# M3351 register map
File version: 1.0
Registers are 32-bit, read-write, reset 0x0 unless marked. A register's access mark holds for its fields unless they carry their own. Offsets are from the block's base; [hi:lo] are bit positions; lines under a group give offsets from that group; {n}, {i} and the like mark numbered series; 'fields as' and 'values as' point back to an identical list.

## PWM0 — PWM Register Map
Base 0x4005C000
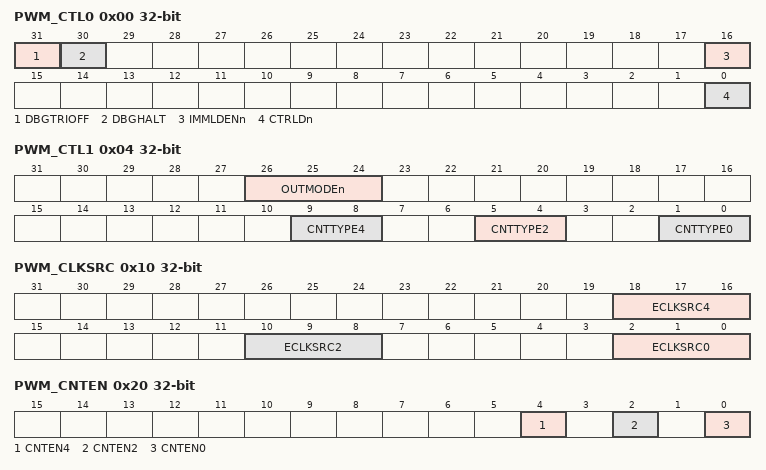
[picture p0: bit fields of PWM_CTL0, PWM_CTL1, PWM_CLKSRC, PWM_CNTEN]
0x00 PWM_CTL0 — PWM Control Register 0
  [31] DBGTRIOFF — ICE Debug Mode Acknowledge Disable Bit (Write Protect). PWM pin will keep output no matter ICE debug mode acknowledged or not. Note: This bit is write protected. Refer to SYS_REGLCTL register.
    0=ICE debug mode acknowledgement effects PWM output; 1=ICE debug mode acknowledgement disabled
  [30] DBGHALT — ICE Debug Mode Counter Halt (Write Protect). If counter halt is enabled, PWM all counters will keep current value until exit ICE debug mode. Note: This bit is write protected. Refer to SYS_REGLCTL register.
    0=ICE debug mode counter halt Disable; 1=ICE debug mode counter halt Enable
  [16] IMMLDENn — Immediately Load Enable Bits. Note: If IMMLDENn is enabled, WINLDENn and CTRLDn will be invalid.
    0=PERIOD will load to PBUF at the end point of each period. CMPDAT will load to CMPBUF at the end point or center point of each period by setting CTRLD bit; 1=PERIOD/CMPDAT will load to PBUF and CMPBUF immediately when software update PERIOD/CMPDAT
  [0] CTRLDn — Center Load Enable Bits. In up-down counter type, PERIOD will load to PBUF at the end point of each period. CMPDAT will load to CMPBUF at the center point of a period.
0x04 PWM_CTL1 — PWM Control Register 1
  [26:24] OUTMODEn — PWM Output Mode. Each bit n controls the output mode of corresponding PWM channel n. Note: When operating in group function, these bits must all set to the same mode.
    0=PWM independent mode; 1=PWM complementary mode
  [9:8] CNTTYPE4 — PWM Counter Behavior Type 4. The two bits control channel5 and channel4
    0=Up counter type (supported in capture mode); 1=Down count type (supported in capture mode); 2=Up-down counter type
  [5:4] CNTTYPE2 — PWM Counter Behavior Type 2. The two bits control channel3 and channel2
    values as CNTTYPE4
  [1:0] CNTTYPE0 — PWM Counter Behavior Type 0. The two bits control channel1 and channel0
    values as CNTTYPE4
0x10 PWM_CLKSRC — PWM Clock Source Register
  [all] fields
    0=PWMx_CLK, x denotes 0 or 1; {v}=TIMER{v-1} overflow (v=1..4)
  [18:16] ECLKSRC4 — PWM_CH45 External Clock Source Select
  [10:8] ECLKSRC2 — PWM_CH23 External Clock Source Select
  [2:0] ECLKSRC0 — PWM_CH01 External Clock Source Select
0x14 PWM_CLKPSC0_1 — PWM Clock Prescale Register 0/1
  [11:0] CLKPSC — PWM Counter Clock Prescale. The clock of PWM counter is decided by clock prescaler. Each PWM pair share one PWM counter clock prescaler. The clock of PWM counter is divided by (CLKPSC+ 1).
0x18 PWM_CLKPSC2_3 — PWM Clock Prescale Register 2/3
  fields as PWM_CLKPSC0_1
0x1C PWM_CLKPSC4_5 — PWM Clock Prescale Register 4/5
  fields as PWM_CLKPSC0_1
0x20 PWM_CNTEN — PWM Counter Enable Register
  [all] fields
    0=PWM Counter and clock prescaler Stop Running; 1=PWM Counter and clock prescaler Start Running
  [4] CNTEN4 — PWM Counter Enable Bit 4
  [2] CNTEN2 — PWM Counter Enable Bit 2
  [0] CNTEN0 — PWM Counter Enable Bit 0
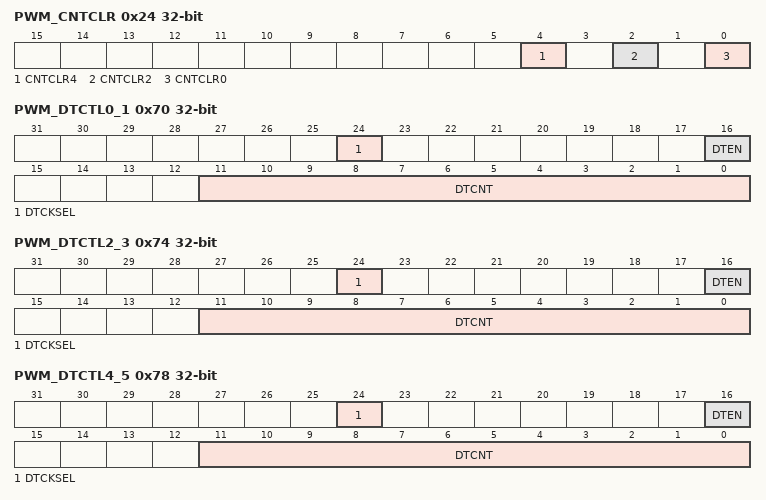
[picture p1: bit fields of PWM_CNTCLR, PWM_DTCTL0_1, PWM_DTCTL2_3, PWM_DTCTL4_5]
0x24 PWM_CNTCLR — PWM Clear Counter Register
  [all] fields
    0=No effect; 1=Clear 16-bit PWM counter to 0000H
  [4] CNTCLR4 — Clear PWM Counter Control Bit 4. It is automatically cleared by hardware.
  [2] CNTCLR2 — Clear PWM Counter Control Bit 2. It is automatically cleared by hardware.
  [0] CNTCLR0 — Clear PWM Counter Control Bit 0. It is automatically cleared by hardware.
0x30 PWM_PERIOD0 — PWM Period Register 0
  [15:0] PERIOD — PWM Period Register. Up-Count mode: In this mode, PWM counter counts from 0 to PERIOD, and restarts from 0. Down-Count mode: In this mode, PWM counter counts from PERIOD to 0, and restarts from PERIOD.
0x38 PWM_PERIOD2 — PWM Period Register 2
  fields as PWM_PERIOD0
0x40 PWM_PERIOD4 — PWM Period Register 4
  fields as PWM_PERIOD0
{0x50+4i} PWM_CMPDAT{i} (i=0..5) — PWM Comparator Register {i}
  [15:0] CMP — PWM Comparator Register. CMP is used to compar e with CNT to generate PWM waveform, interrupt and trigger EADC/ /DAC. In independent mode, PWM_CMPDAT0~5 denote as 6 independent PWM_CH0~5 compared point. In complementary mode, PWM_CMPDAT0, 2, 4 denote as first compared point, and PWM_CMPDAT1, 3, 5 denote as second compared point for the corresponding 3 complementary pairs PWM_CH0 and PWM_CH1, PWM_CH2 and PWM_CH3, PWM_CH4 and PWM_CH5.
0x70 PWM_DTCTL0_1 — PWM Dead-time Control Register 0/1
  [24] DTCKSEL — Dead-time Clock Select (Write Protect). Note: This bit is write protected. Refer to SYS_REGLCTL register.
    0=Dead-time clock source from PWM_CLK; 1=Dead-time clock source from prescaler output
  [16] DTEN — Enable Dead-time Insertion for PWM Pair (Write Protect). Dead-time insertion is only active when this pair of complementary PWM is enabled. If dead- time insertion is inactive, the outputs of pin pair are complementary without any delay. Note: This bit is write protected. Refer to SYS_REGLCTL register. Note: PWM pair means PWM_CH0, PWM_CH1 are a pair, PWM_CH2, PWM_CH3 are a pair and PWM_CH4, PWM_CH5 are a pair.
    0=Dead-time insertion Disabled on the pin pair; 1=Dead-time insertion Enabled on the pin pair
  [11:0] DTCNT — Dead-time Counter (Write Protect). The dead-time can be calculated from the following formula: Note: This bit is write protected. Refer to SYS_REGLCTL register.
0x74 PWM_DTCTL2_3 — PWM Dead-time Control Register 2/3
  fields as PWM_DTCTL0_1
0x78 PWM_DTCTL4_5 — PWM Dead-time Control Register 4/5
  fields as PWM_DTCTL0_1
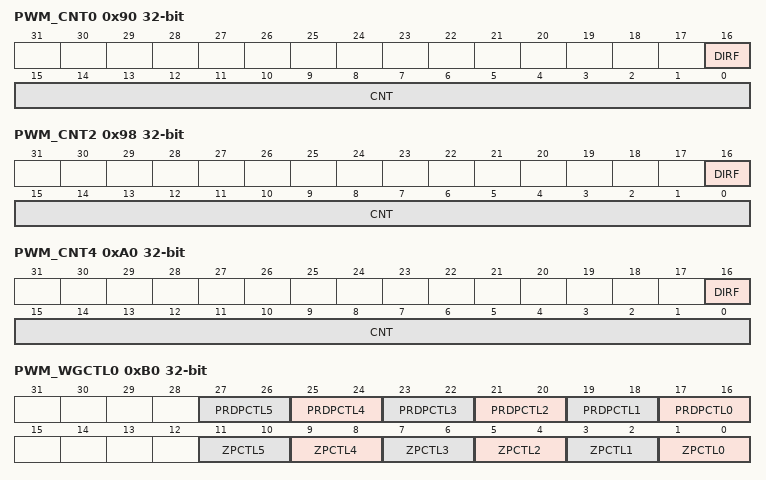
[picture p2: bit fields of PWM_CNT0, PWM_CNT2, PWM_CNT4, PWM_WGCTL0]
0x90 PWM_CNT0 ro — PWM Counter Register 0
  [16] DIRF — PWM Direction Indicator Flag (Read Only)
    0=Counter is counting down; 1=Counter is counting up
  [15:0] CNT — PWM Data Register (Read Only). User can monitor CNT to know the current value in 16-bit period counter.
0x98 PWM_CNT2 ro — PWM Counter Register 2
  fields as PWM_CNT0
0xA0 PWM_CNT4 ro — PWM Counter Register 4
  fields as PWM_CNT0
0xB0 PWM_WGCTL0 — PWM Generation Register 0
  [2n+17:2n+16] PRDPCTL{n} (n=0..5) — PWM Period/Center Point Control. Note 1: PWM can control output level when PWM counter counts to (PERIODn+1). Note 2: This bit is center point control when PWM counter operating in up-down counter type.
    0=Do nothing; 1=PWM period/center point output Low; 2=PWM period/center point output High; 3=PWM period/center point output Toggle
  [2n+1:2n] ZPCTL{n} (n=0..5) — PWM Zero Point Control. Note: PWM can control output level when PWM counter counts to 0.
    0=Do nothing; 1=PWM zero point output Low; 2=PWM zero point output High; 3=PWM zero point output Toggle
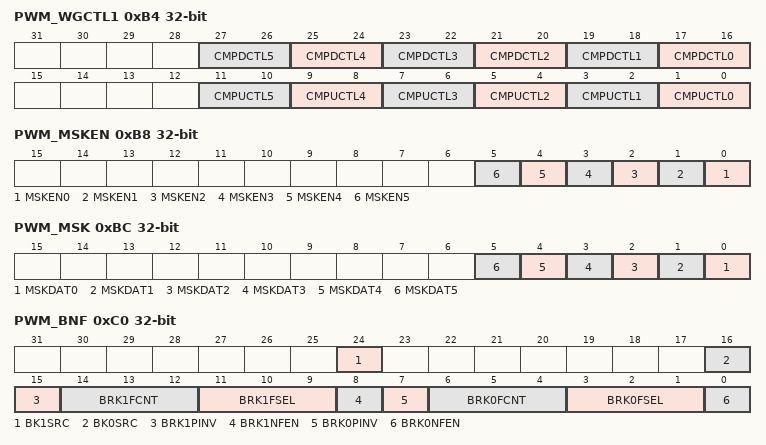
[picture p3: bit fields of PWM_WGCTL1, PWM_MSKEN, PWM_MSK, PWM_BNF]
0xB4 PWM_WGCTL1 — PWM Generation Register 1
  [2n+17:2n+16] CMPDCTL{n} (n=0..5) — PWM Compare Down Point Control. Note 1: PWM can control output level when PWM counter counts down to CMPDAT. Note 2: In complementary mode, CMPDCTL1, 3, 5 is used as another CMPDCTL for channel 0, 2, 4.
    0=Do nothing; 1=PWM compare down point output Low; 2=PWM compare down point output High; 3=PWM compare down point output Toggle
  [2n+1:2n] CMPUCTL{n} (n=0..5) — PWM Compare Up Point Control. Note 1: PWM can control output level when PWM counter counts up to CMPDAT. Note 2: In complementary mode, CMPUCTL1, 3, 5 is used as another CMPUCTL for channel 0, 2, 4.
    0=Do nothing; 1=PWM compare up point output Low; 2=PWM compare up point output High; 3=PWM compare up point output Toggle
0xB8 PWM_MSKEN — PWM Mask Enable Register
  [all] fields
    0=PWM output signal is non-masked; 1=PWM output signal is masked and output MSKDATn data
  [n] MSKEN{n} (n=0..5) — PWM Mask Enable Bits. The PWM output signal will be masked when this bit is enabled. The corresponding PWM channel n will output MSKDATn (PWM_MSK[5:0]) data.
0xBC PWM_MSK — PWM Mask Data Register
  [all] fields
    0=Output logic low to PWM channel n; 1=Output logic high to PWM channel n
  [n] MSKDAT{n} (n=0..5) — PWM Mask Data Bit. This data bit control the state of PWMn output pin, if corresponding mask function is enabled. Each bit n controls the corresponding PWM channel n.
0xC0 PWM_BNF — PWM Brake Noise Filter Register
  [24] BK1SRC — Brake 1 Pin Source Select. For PWM0 setting:
    0=Brake 1 pin source come from PWM0_BRAKE1. Brake 1 pin source come from PWM1_BRAKE1; 1=Brake 1 pin source come from PWM1_BRAKE1. Brake 1 pin source come from PWM0_BRAKE1
  [16] BK0SRC — Brake 0 Pin Source Select. For PWM0 setting:
    0=Brake 0 pin source come from PWM0_BRAKE0. Brake 0 pin source come from PWM1_BRAKE0; 1=Brake 0 pin source come from PWM1_BRAKE0. Brake 0 pin source come from PWM0_BRAKE0
  [15] BRK1PINV — Brake 1 Pin Inverse
    0=Brake pin event will be detected if PWMx_BRAKE1 pin status transfer from low to high in edge-detect, or pin status is high in level-detect; 1=Brake pin event will be detected if PWMx_BRAKE1 pin status transfer from high to low in edge-detect, or pin status is low in level-detect
  [14:12] BRK1FCNT — Brake 1 Edge Detector Filter Count. The register bits control the Brake1 filter counter to count from 0 to BRK1FCNT.
  [11:9] BRK1FSEL — Brake 1 Edge Detector Filter Clock Selection
    0=Filter clock = HCLK; 1=Filter clock = HCLK/2; 2=Filter clock = HCLK/4; 3=Filter clock = HCLK/8; 4=Filter clock = HCLK/16; 5=Filter clock = HCLK/32; 6=Filter clock = HCLK/64; 7=Filter clock = HCLK/128
  [8] BRK1NFEN — PWM Brake 1 Noise Filter Enable Bit
    0=Noise filter of PWM Brake 1 Disabled; 1=Noise filter of PWM Brake 1 Enabled
  [7] BRK0PINV — Brake 0 Pin Inverse
    0=brake pin event will be detected if PWMx_BRAKE0 pin status transfer from low to high in edge-detect, or pin status is high in level-detect; 1=brake pin event will be detected if PWMx_BRAKE0 pin status transfer from high to low in edge-detect, or pin status is low in level-detect
  [6:4] BRK0FCNT — Brake 0 Edge Detector Filter Count. The register bits control the Brake0 filter counter to count from 0 to BRK1FCNT.
  [3:1] BRK0FSEL — Brake 0 Edge Detector Filter Clock Selection
    values as BRK1FSEL
  [0] BRK0NFEN — PWM Brake 0 Noise Filter Enable Bit
    0=Noise filter of PWM Brake 0 Disabled; 1=Noise filter of PWM Brake 0 Enabled
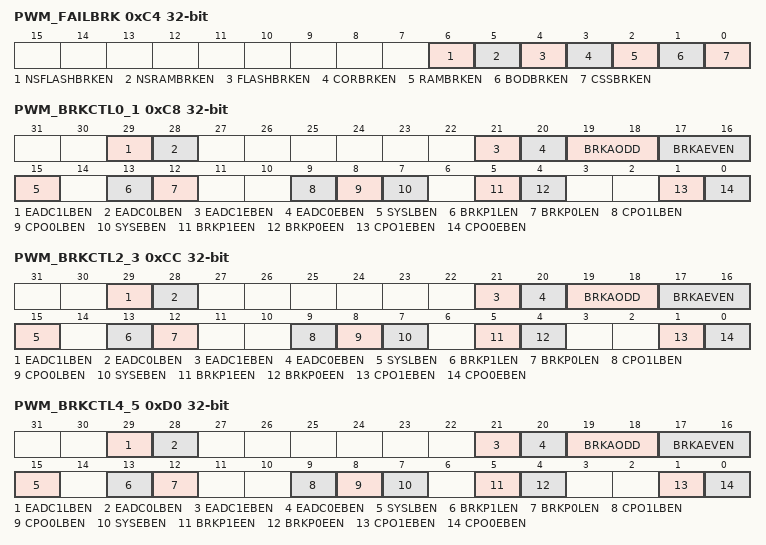
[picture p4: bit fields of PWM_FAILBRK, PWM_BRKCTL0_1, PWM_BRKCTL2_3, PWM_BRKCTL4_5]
0xC4 PWM_FAILBRK — PWM System Fail Brake Control Register
  [6] NSFLASHBRKEN — FLASH non security ECC Error Detection Trigger PWM Brake Function Enable Bit
    0=Brake Function triggered by FLASH non security ECCerror detection Disabled; 1=Brake Function triggered by FLASH non security ECCerror detection Enabled
  [5] NSRAMBRKEN — SRAM non security ECC Error Detection Trigger PWM Brake Function Enable Bit
    0=Brake Function triggered by SRAM non security ECCerror detection Disabled; 1=Brake Function triggered by SRAM non security ECCerror detection Enabled
  [4] FLASHBRKEN — FLASH ECC Error Detection Trigger PWM Brake Function Enable Bit
    0=Brake Function triggered by FLASH ECCerror detection Disabled; 1=Brake Function triggered by FLASH ECCerror detection Enabled
  [3] CORBRKEN — Core Lockup Detection Trigger PWM Brake Function Enable Bit
    0=Brake Function triggered by Core lockup detection Disabled; 1=Brake Function triggered by Core lockup detection Enabled
  [2] RAMBRKEN — SRAM ECC Error Detection Trigger PWM Brake Function Enable Bit
    0=Brake Function triggered by SRAM ECCerror detection Disabled; 1=Brake Function triggered by SRAM ECCerror detection Enabled
  [1] BODBRKEN — Brown-out Detection Trigger PWM Brake Function Enable Bit
    0=Brake Function triggered by BOD Disabled; 1=Brake Function triggered by BOD Enabled
  [0] CSSBRKEN — Clock Security System Detection Trigger PWM Brake Function Enable Bit
    0=Brake Function triggered by CSS detection Disabled; 1=Brake Function triggered by CSS detection Enabled
0xC8 PWM_BRKCTL0_1 — PWM Brake Edge Detect Control Register 0/1
  [29] EADC1LBEN — Enable EADC1 Result Monitor as Level-detect Brake Source (Write Protect). Note: This bit is write protected. Refer to SYS_REGLCTL register.
    0=EADC1RM as level-detect brake source Disabled; 1=EADC1RM as level-detect brake source Enabled
  [28] EADC0LBEN — Enable EADC0 Result Monitor as Level-detect Brake Source (Write Protect). Note: This bit is write protected. Refer to SYS_REGLCTL register.
    0=EADC0RM as level-detect brake source Disabled; 1=EADC0RM as level-detect brake source Enabled
  [21] EADC1EBEN — Enable EADC1 Result Monitor as Edge-detect Brake Source (Write Protect). Note: This bit is write protected. Refer to SYS_REGLCTL register.
    0=EADC1RM as edge-detect brake source Disabled; 1=EADC1RM as edge-detect brake source Enabled
  [20] EADC0EBEN — Enable EADC0 Result Monitor as Edge-detect Brake Source (Write Protect). Note: This bit is write protected. Refer to SYS_REGLCTL register.
    0=EADC0RM as edge-detect brake source Disabled; 1=EADC0RM as edge-detect brake source Enabled
  [19:18] BRKAODD — PWM Brake Action Select for Odd Channel (Write Protect). Note: These bits are write protected. Refer to SYS_REGLCTL register.
    0=PWM odd channel level-detect or edge-detect brake function not affect channel output; 1=PWM odd channel output tri-state when level-detect or edge-detect brake happened; 2=PWM odd channel output low level when level-detect or edge-detect brake happened; 3=PWM odd channel output high level when level-detect or edge-detect brake happened
  [17:16] BRKAEVEN — PWM Brake Action Select for Even Channel (Write Protect). Note: These bits are write protected. Refer to SYS_REGLCTL register.
    0=PWM even channel level-detect or edge-detect brake function not affect channel output; 1=PWM even channel output tri-state when level-detect or edge-detect brake happened; 2=PWM even channel output low level when level-detect or edge-detect brake happened; 3=PWM even channel output high level when level-detect or edge-detect brake happened
  [15] SYSLBEN — Enable System Fail As Level-detect Brake Source (Write Protect). Note: This bit is write protected. Refer to SYS_REGLCTL register.
    0=System Fail condition as level-detect brake source Disabled; 1=System Fail condition as level-detect brake source Enabled
  [13] BRKP1LEN — Enable BKP1 Pin As Level-detect Brake Source (Write Protect). Note: This bit is write protected. Refer to SYS_REGLCTL register.
    0=PWMx_BRAKE1 pin as level-detect brake source Disabled; 1=PWMx_BRAKE1 pin as level-detect brake source Enabled
  [12] BRKP0LEN — Enable BKP0 Pin As Level-detect Brake Source (Write Protect). Note: This bit is write protected. Refer to SYS_REGLCTL register.
    0=PWMx_BRAKE0 pin as level-detect brake source Disabled; 1=PWMx_BRAKE0 pin as level-detect brake source Enabled
  [9] CPO1LBEN — Enable ACMP1_O Digital Output As Level-detect Brake Source (Write Protect). Note: This register is write protected. Refer toSYS_REGLCTL register.
    0=ACMP1_O as level-detect brake source Disabled; 1=ACMP1_O as level-detect brake source Enabled
  [8] CPO0LBEN — Enable ACMP0_O Digital Output As Level-detect Brake Source (Write Protect). Note: This register is write protected. Refer toSYS_REGLCTL register.
    0=ACMP0_O as level-detect brake source Disabled; 1=ACMP0_O as level-detect brake source Enabled
  [7] SYSEBEN — Enable System Fail As Edge-detect Brake Source (Write Protect). Note: This bit is write protected. Refer to SYS_REGLCTL register.
    0=System Fail condition as edge-detect brake source Disabled; 1=System Fail condition as edge-detect brake source Enabled
  [5] BRKP1EEN — Enable PWMx_BRAKE1 Pin As Edge-detect Brake Source (Write Protect). Note: This bit is write protected. Refer to SYS_REGLCTL register.
    0=BKP1 pin as edge-detect brake source Disabled; 1=BKP1 pin as edge-detect brake source Enabled
  [4] BRKP0EEN — Enable PWMx_BRAKE0 Pin As Edge-detect Brake Source (Write Protect). Note: This bit is write protected. Refer to SYS_REGLCTL register.
    0=BKP0 pin as edge-detect brake source Disabled; 1=BKP0 pin as edge-detect brake source Enabled
  [1] CPO1EBEN — Enable ACMP1_O Digital Output As Edge-detect Brake Source (Write Protect). Note: This register is write protected. Refer toSYS_REGLCTL register.
    0=ACMP1_O as edge-detect brake source Disabled; 1=ACMP1_O as edge-detect brake source Enabled
  [0] CPO0EBEN — Enable ACMP0_O Digital Output As Edge-detect Brake Source (Write Protect). Note: This register is write protected. Refer toSYS_REGLCTL register.
    0=ACMP0_O as edge-detect brake source Disabled; 1=ACMP0_O as edge-detect brake source Enabled
0xCC PWM_BRKCTL2_3 — PWM Brake Edge Detect Control Register 2/3
  fields as PWM_BRKCTL0_1
0xD0 PWM_BRKCTL4_5 — PWM Brake Edge Detect Control Register 4/5
  fields as PWM_BRKCTL0_1
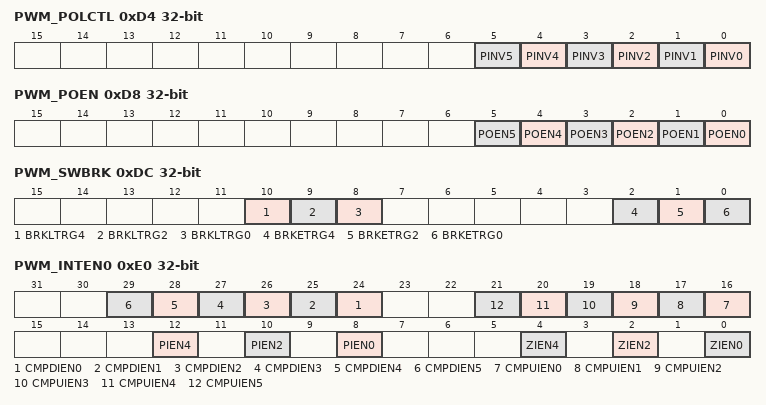
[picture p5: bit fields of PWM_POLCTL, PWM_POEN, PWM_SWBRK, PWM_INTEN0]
0xD4 PWM_POLCTL — PWM Pin Polar Inverse Register
  [all] fields
    0=PWM output polar inverse Disabled; 1=PWM output polar inverse Enabled
  [n] PINV{n} (n=0..5) — PWM PIN Polar Inverse Control. The register controls polarity state of PWM output.
0xD8 PWM_POEN — PWM Output Enable Register
  [all] fields
    0=PWM pin at tri-state; 1=PWM pin in output mode
  [n] POEN{n} (n=0..5) — PWM Pin Output Enable Bits
0xDC PWM_SWBRK wo — PWM Software Brake Control Register
  [10] BRKLTRG4 — PWM Level Brake Software Trigger (Write Only) (Write Protect). Write 1 to this bit will trigger level brake, and set BRKLIFn to 1 in PWM_INTSTS1 register. Note: This bit is write protected. Refer to SYS_REGLCTL register.
  [9] BRKLTRG2 — PWM Level Brake Software Trigger (Write Only) (Write Protect). Write 1 to this bit will trigger level brake, and set BRKLIFn to 1 in PWM_INTSTS1 register. Note: This bit is write protected. Refer to SYS_REGLCTL register.
  [8] BRKLTRG0 — PWM Level Brake Software Trigger (Write Only) (Write Protect). Write 1 to this bit will trigger level brake, and set BRKLIFn to 1 in PWM_INTSTS1 register. Note: This bit is write protected. Refer to SYS_REGLCTL register.
  [2] BRKETRG4 — PWM Edge Brake Software Trigger (Write Only) (Write Protect). Write 1 to this bit will trigger Edge brake, and set BRKEIFn to 1 in PWM_INTSTS1 register. Note: This bit is write protected. Refer to SYS_REGLCTL register.
  [1] BRKETRG2 — PWM Edge Brake Software Trigger (Write Only) (Write Protect). Write 1 to this bit will trigger Edge brake, and set BRKEIFn to 1 in PWM_INTSTS1 register. Note: This bit is write protected. Refer to SYS_REGLCTL register.
  [0] BRKETRG0 — PWM Edge Brake Software Trigger (Write Only) (Write Protect). Write 1 to this bit will trigger Edge brake, and set BRKEIFn to 1 in PWM_INTSTS1 register. Note: This bit is write protected. Refer to SYS_REGLCTL register.
0xE0 PWM_INTEN0 — PWM Interrupt Enable Register 0
  [n+24] CMPDIEN{n} (n=0..5) — PWM Compare Down Count Interrupt Enable Bits. Note: In complementary mode, CMPDIEN1, 3, 5 is used as another CMPDIEN for channel 0, 2, 4.
    0=Compare down count interrupt Disabled; 1=Compare down count interrupt Enabled
  [n+16] CMPUIEN{n} (n=0..5) — PWM Compare Up Count Interrupt Enable Bits. Each bit n controls the corresponding PWM channel n. Note: In complementary mode, CMPUIEN1, 3, 5 is used as another CMPUIEN for channel 0, 2, 4.
    0=Compare up count interrupt Disabled; 1=Compare up count interrupt Enabled
  [12] PIEN4 — PWM Period Point Interrupt Enable Bit 4. Note: When up-down counter type, period point means center point.
    0=Period point interrupt Disabled; 1=Period point interrupt Enabled
  [10] PIEN2 — PWM Period Point Interrupt Enable Bit 2. Note: When up-down counter type, period point means center point.
    values as PIEN4
  [8] PIEN0 — PWM Period Point Interrupt Enable Bit 0. Note: When up-down counter type, period point means center point.
    values as PIEN4
  [4] ZIEN4 — PWM Zero Point Interrupt Enable Bit 4. Note: Odd channels will read always 0 at complementary mode.
    0=Zero point interrupt Disabled; 1=Zero point interrupt Enabled
  [2] ZIEN2 — PWM Zero Point Interrupt Enable Bit 2. Note: Odd channels will read always 0 at complementary mode.
    values as ZIEN4
  [0] ZIEN0 — PWM Zero Point Interrupt Enable Bit 0. Note: Odd channels will read always 0 at complementary mode.
    values as ZIEN4
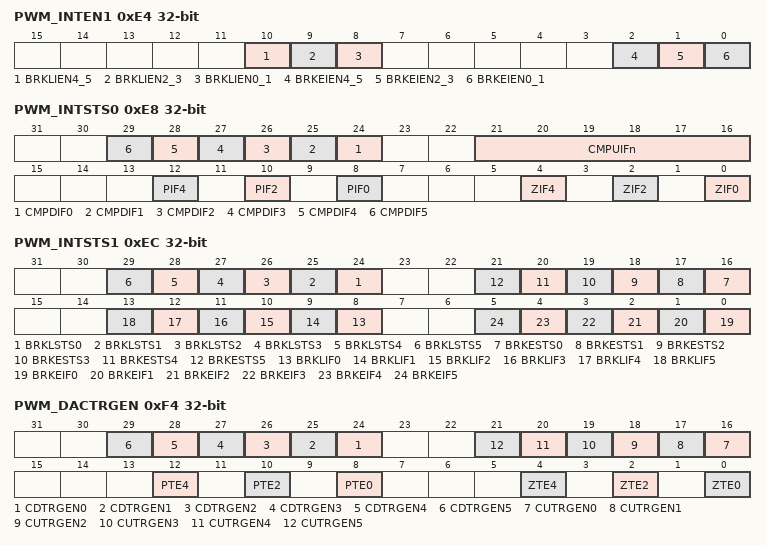
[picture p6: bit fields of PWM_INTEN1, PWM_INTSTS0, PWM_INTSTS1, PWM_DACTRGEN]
0xE4 PWM_INTEN1 — PWM Interrupt Enable Register 1
  [10] BRKLIEN4_5 — PWM Level-detect Brake Interrupt Enable for Channel4/5 (Write Protect). Note: This bit is write protected. Refer to SYS_REGLCTL register.
    0=Level-detect Brake interrupt for channel4/5 Disabled; 1=Level-detect Brake interrupt for channel4/5 Enabled
  [9] BRKLIEN2_3 — PWM Level-detect Brake Interrupt Enable for Channel2/3 (Write Protect). Note: This bit is write protected. Refer to SYS_REGLCTL register.
    0=Level-detect Brake interrupt for channel2/3 Disabled; 1=Level-detect Brake interrupt for channel2/3 Enabled
  [8] BRKLIEN0_1 — PWM Level-detect Brake Interrupt Enable for Channel0/1 (Write Protect). Note: This bit is write protected. Refer to SYS_REGLCTL register.
    0=Level-detect Brake interrupt for channel0/1 Disabled; 1=Level-detect Brake interrupt for channel0/1 Enabled
  [2] BRKEIEN4_5 — PWM Edge-detect Brake Interrupt Enable for Channel4/5 (Write Protect). Note: This bitr is write protected. Refer to SYS_REGLCTL register.
    0=Edge-detect Brake interrupt for channel4/5 Disabled; 1=Edge-detect Brake interrupt for channel4/5 Enabled
  [1] BRKEIEN2_3 — PWM Edge-detect Brake Interrupt Enable for Channel2/3 (Write Protect). Note: This bit is write protected. Refer to SYS_REGLCTL register.
    0=Edge-detect Brake interrupt for channel2/3 Disabled; 1=Edge-detect Brake interrupt for channel2/3 Enabled
  [0] BRKEIEN0_1 — PWM Edge-detect Brake Interrupt Enable for Channel0/1 (Write Protect). Note: This bit is write protected. Refer to SYS_REGLCTL register.
    0=Edge-detect Brake interrupt for channel0/1 Disabled; 1=Edge-detect Brake interrupt for channel0/1 Enabled
0xE8 PWM_INTSTS0 — PWM Interrupt Flag Register 0
  [n+24] CMPDIF{n} (n=0..5) — PWM Compare Down Count Interrupt Flag. Flag is set by hardware when PWM counter down count and reaches PWM_CMPDATn, software can clear this bit by writing 1 to it. Note: In complementary mode, CMPDIF1, 3, 5 is used as another CMPDIF for channel 0, 2, 4.
  [21:16] CMPUIFn — PWM Compare Up Count Interrupt Flag. Flag is set by hardware when PWM counter up count and reaches PWM_CMPDATn, software can clear this bit by writing 1 to it. Note: In complementary mode, CMPUIF1, 3, 5 is used as another CMPUIF for channel 0, 2, 4.
  [12] PIF4 — PWM Period Point Interrupt Flag 4. This bit is set by hardware when PWM_CH4 counter reaches PWM_PERIOD4. Note: This bit can be cleared to 0 by software writing 1.
  [10] PIF2 — PWM Period Point Interrupt Flag 2. This bit is set by hardware when PWM_CH2 counter reaches PWM_PERIOD2. Note: This bit can be cleared to 0 by software writing 1.
  [8] PIF0 — PWM Period Point Interrupt Flag 0. This bit is set by hardware when PWM_CH0 counter reaches PWM_PERIOD0. Note: This bit can be cleared to 0 by software writing 1.
  [4] ZIF4 — PWM Zero Point Interrupt Flag 4. This bit is set by hardware when PWM_CH4 counter reaches 0. Note: This bit can be cleared to 0 by software writing 1.
  [2] ZIF2 — PWM Zero Point Interrupt Flag 2. This bit is set by hardware when PWM_CH2 counter reaches 0. Note: This bit can be cleared to 0 by software writing 1.
  [0] ZIF0 — PWM Zero Point Interrupt Flag 0. This bit is set by hardware when PWM_CH0 counter reaches 0. Note: This bit can be cleared to 0 by software writing 1.
0xEC PWM_INTSTS1 — PWM Interrupt Flag Register 1
  [n+24] BRKLSTS{n} (n=0..5) — PWM Channel n Level-detect Brake Status (Read Only). Note: This bit is read only and auto cleared by hardware. When enabled brake source return to high level, PWM will release brake state until current PWM period finished. The PWM waveform will start output from next full PWM period.
    0=PWM channel n level-detect brake state is released; 1=When PWM channel n level-detect brake detects a falling edge of any enabled brake source; this flag will be set to indicate the PWM channel n at brake state
  [n+16] BRKESTS{n} (n=0..5) — PWM Channel n Edge-detect Brake Status (Read Only). Note: This bit is read only and auto cleared by hardware. When edge-detect brake interrupt flag is cleared, PWM will release brake state until current PWM period finished. The PWM waveform will start output from next full PWM period.
    0=PWM channel n edge-detect brake state is released; 1=When PWM channel n edge-detect brake detects a falling edge of any enabled brake source; this flag will be set to indicate the PWM channel n at brake state
  [n+8] BRKLIF{n} (n=0..5) — PWM Channel n Level-detect Brake Interrupt Flag (Write Protect). Note: This bit is write protected. Refer to SYS_REGLCTL register.
    0=PWM channel n level-detect brake event do not happened; 1=When PWM channel n level-detect brake event happened, this bit is set to 1, writing 1 to clear
  [n] BRKEIF{n} (n=0..5) — PWM Channel n Edge-detect Brake Interrupt Flag (Write Protect). Note: This bit is write protected. Refer to SYS_REGLCTL register.
    0=PWM channel n edge-detect brake event do not happened; 1=When PWM channel n edge-detect brake event happened, this bit is set to 1, writing 1 to clear
0xF4 PWM_DACTRGEN — PWM Trigger DAC Enable Register
  [n+24] CDTRGEN{n} (n=0..5) — PWM Compare Down Count Point Trigger DAC Enable Bits. PWM can trigger DAC to start action when PWM counter down count to CMP if this bit is set to1. Note 1: This bit should keep at 0 when PWM counter operating in up counter type. Note 2: In complementary mode, CDTRGEN1, 3, 5 is used as another CDTRGEN for channel 0, 2, 4.
    0=PWM Compare Down count point trigger DAC function Disabled; 1=PWM Compare Down count point trigger DAC function Enabled
  [n+16] CUTRGEN{n} (n=0..5) — PWM Compare Up Count Point Trigger DAC Enable Bits. PWM can trigger DAC to start action when PWM counter counts up to CMP if this bit is set to1. Note 1: This bit should keep at 0 when PWM counter operating in down counter type. Note 2: In complementary mode, CUTRGEN1, 3, 5 is used as another CUTRGEN for channel 0, 2, 4.
    0=PWM Compare Up point trigger DAC function Disabled; 1=PWM Compare Up point trigger DAC function Enabled
  [12] PTE4 — PWM Period Point Trigger DAC Enable Bit 4. PWM can trigger DAC to start action when PWM counter counts up to (PERIODn+1) if this bit is set to1.
    0=PWM period point trigger DAC function Disabled; 1=PWM period point trigger DAC function Enabled
  [10] PTE2 — PWM Period Point Trigger DAC Enable Bit 2. PWM can trigger DAC to start action when PWM counter counts up to (PERIODn+1) if this bit is set to1.
    values as PTE4
  [8] PTE0 — PWM Period Point Trigger DAC Enable Bit 0. PWM can trigger DAC to start action when PWM counter counts up to (PERIODn+1) if this bit is set to1.
    values as PTE4
  [4] ZTE4 — PWM Zero Point Trigger DAC Enable Bit 4. PWM can trigger EADC/DAC/DMA to start action when PWM counter down count to zero if this bit is set to1.
    values as PTE4
  [2] ZTE2 — PWM Zero Point Trigger DAC Enable Bit 2. PWM can trigger EADC/DAC/DMA to start action when PWM counter down count to zero if this bit is set to1.
    values as PTE4
  [0] ZTE0 — PWM Zero Point Trigger DAC Enable Bit 0. PWM can trigger EADC/DAC/DMA to start action when PWM counter down count to zero if this bit is set to1.
    values as PTE4
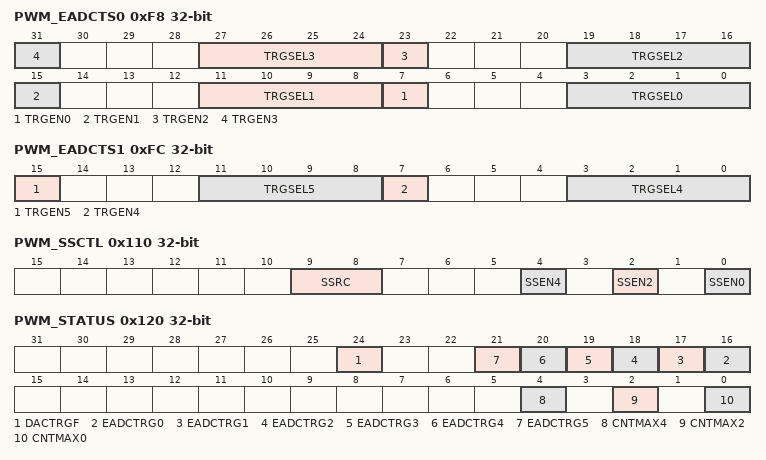
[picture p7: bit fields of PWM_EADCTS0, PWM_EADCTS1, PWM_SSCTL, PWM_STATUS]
0xF8 PWM_EADCTS0 — PWM Trigger EADC Source Select Register 0
  [8n+7] TRGEN{n} (n=0..3) — PWM_CH{n} Trigger EADC Enable Bit
    0=PWM_CH{n} Trigger EADC function Disabled; 1=PWM_CH{n} Trigger EADC function Enabled
  [27:24] TRGSEL3 — PWM_CH3 Trigger EADC Source Select
    0=PWM_CH2 zero point; 1=PWM_CH2 period point; 2=PWM_CH2 zero or period point; 3=PWM_CH2 up-count CMPDAT point; 4=PWM_CH2 down-count CMPDAT point; 8=PWM_CH3 up-count CMPDAT point; 9=PWM_CH3 down-count CMPDAT point
  [19:16] TRGSEL2 — PWM_CH2 Trigger EADC Source Select
    values as TRGSEL3
  [11:8] TRGSEL1 — PWM_CH1 Trigger EADC Source Select
    0=PWM_CH0 zero point; 1=PWM_CH0 period point; 2=PWM_CH0 zero or period point; 3=PWM_CH0 up-count CMPDAT point; 4=PWM_CH0 down-count CMPDAT point; 8=PWM_CH1 up-count CMPDAT point; 9=PWM_CH1 down-count CMPDAT point
  [3:0] TRGSEL0 — PWM_CH0 Trigger EADC Source Select
    values as TRGSEL1
0xFC PWM_EADCTS1 — PWM Trigger EADC Source Select Register 1
  [15] TRGEN5 — PWM_CH5 Trigger EADC Enable Bit
    0=PWM_CH5 Trigger EADC function Disabled; 1=PWM_CH5 Trigger EADC function Enabled
  [11:8] TRGSEL5 — PWM_CH5 Trigger EADC Source Select
    0=PWM_CH4 zero point; 1=PWM_CH4 period point; 2=PWM_CH4 zero or period point; 3=PWM_CH4 up-count CMPDAT point; 4=PWM_CH4 down-count CMPDAT point; 8=PWM_CH5 up-count CMPDAT point; 9=PWM_CH5 down-count CMPDAT point
  [7] TRGEN4 — PWM_CH4 Trigger EADC Enable Bit
    0=PWM_CH4 Trigger EADC function Disabled; 1=PWM_CH4 Trigger EADC function Enabled
  [3:0] TRGSEL4 — PWM_CH4 Trigger EADC Source Select
    values as TRGSEL5
0x110 PWM_SSCTL — PWM Synchronous Start Control Register
  [9:8] SSRC — PWM Synchronous Start Source Select Bits
    0=Synchronous start source come from PWM0; 1=Synchronous start source come from PWM1; 2=Synchronous start source come from BPWM0; 3=Synchronous start source come from BPWM1
  [4] SSEN4 — PWM Synchronous Start Function Enable Bit 4. When synchronous start function is enabled, the PWM_CH4 counter enable bit (CNTEN4) can be enabled by writing PWM synchronous start trigger bit (CNTSEN).
    0=PWM synchronous start function Disabled; 1=PWM synchronous start function Enabled
  [2] SSEN2 — PWM Synchronous Start Function Enable Bit 2. When synchronous start function is enabled, the PWM_CH2 counter enable bit (CNTEN2) can be enabled by writing PWM synchronous start trigger bit (CNTSEN).
    values as SSEN4
  [0] SSEN0 — PWM Synchronous Start Function Enable Bit 0. When synchronous start function is enabled, the PWM_CH0 counter enable bit (CNTEN0) can be enabled by writing PWM synchronous start trigger bit (CNTSEN).
    values as SSEN4
0x114 PWM_SSTRG wo — PWM Synchronous Start Trigger Register
  [0] CNTSEN — PWM Counter Synchronous Start Enable (Write Only). PWM counter synchronous enable function is used to make selected PWM channels (include PWM0_CHx and PWM1_CHx) start counting at the same time.
0x120 PWM_STATUS
  [24] DACTRGF — DAC Start of Conversion Flag. Note: This bit can be cleared by software writing 1.
    0=No DAC start of conversion trigger event has occurred; 1=A DAC start of conversion trigger event has occurred
  [n+16] EADCTRG{n} (n=0..5) — EADC Start of Conversion Status. Note: This bit can be cleared by software writing 1.
    0=Indicates no EADC start of conversion trigger event has occurred; 1=An EADC start of conversion trigger event has occurred
  [4] CNTMAX4 — Time-base Counter 4 Equal to 0xFFFF Latched Flag. Note: This bit can be cleared by software writing 1.
    0=The time-base counter never reached its maximum value 0xFFFF; 1=The time-base counter reached its maximum value
  [2] CNTMAX2 — Time-base Counter 2 Equal to 0xFFFF Latched Flag. Note: This bit can be cleared by software writing 1.
    0=indicates the time-base counter never reached its maximum value 0xFFFF; 1=indicates the time-base counter reached its maximum value
  [0] CNTMAX0 — Time-base Counter 0 Equal to 0xFFFF Latched Flag. Note: This bit can be cleared by software writing 1.
    values as CNTMAX2
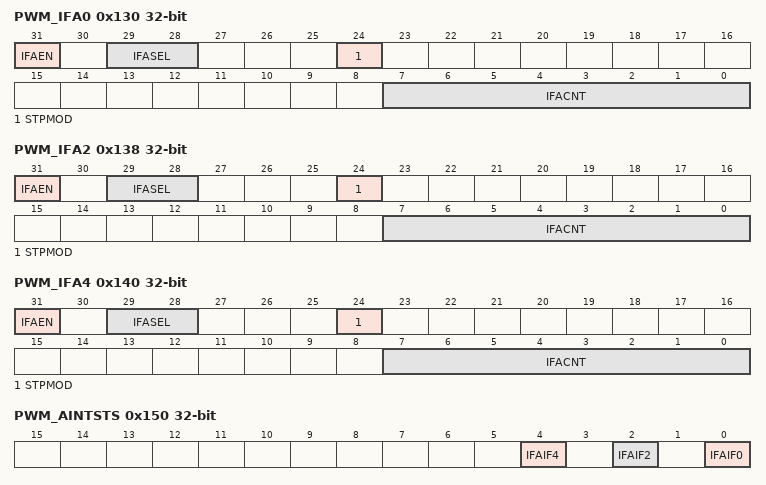
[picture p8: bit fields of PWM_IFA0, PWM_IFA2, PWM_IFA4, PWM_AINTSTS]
0x130 PWM_IFA0 — PWM Interrupt Flag Accumulator Register 0
  [31] IFAEN — PWM_CHn Interrupt Flag Accumulator Enable Bits
    0=PWM_CHn interrupt flag accumulator Disabled; 1=PWM_CHn interrupt flag accumulator Enabled
  [29:28] IFASEL — PWM_CHn Interrupt Flag Accumulator Source Select
    0=PWM_CHn zero point; 1=PWM_CHn period in channel n; 2=PWM_CHn up-count compared point; 3=PWM_CHn down-count compared point
  [24] STPMOD — PWM_CHn Accumulator Stop Mode Enable Bits
    0=PWM_CHn Stop Mode Disable; 1=PWM_CHn Stop Mode Enable
  [7:0] IFACNT — PWM_CHn Interrupt Flag Counter. The register sets the count number which defines (IFACNT+1) times of PWM_CHn period occurs to set bit IFAIFn to request the PWM period interrupt. PWM flag will be set in every IFACNT[15:0] times of PWM period.
0x138 PWM_IFA2 — PWM Interrupt Flag Accumulator Register 2
  fields as PWM_IFA0
0x140 PWM_IFA4 — PWM Interrupt Flag Accumulator Register 4
  fields as PWM_IFA0
0x150 PWM_AINTSTS — PWM Accumulator Interrupt Flag Register
  [4] IFAIF4 — PWM_CH4 Interrupt Flag Accumulator Interrupt Flag. Flag is set by hardware when condition match IFASEL in PWM_IFAn register, software can clear this bit by writing 1 to it.
  [2] IFAIF2 — PWM_CH2 Interrupt Flag Accumulator Interrupt Flag. Flag is set by hardware when condition match IFASEL in PWM_IFAn register, software can clear this bit by writing 1 to it.
  [0] IFAIF0 — PWM_CH0 Interrupt Flag Accumulator Interrupt Flag. Flag is set by hardware when condition match IFASEL in PWM_IFAn register, software can clear this bit by writing 1 to it.
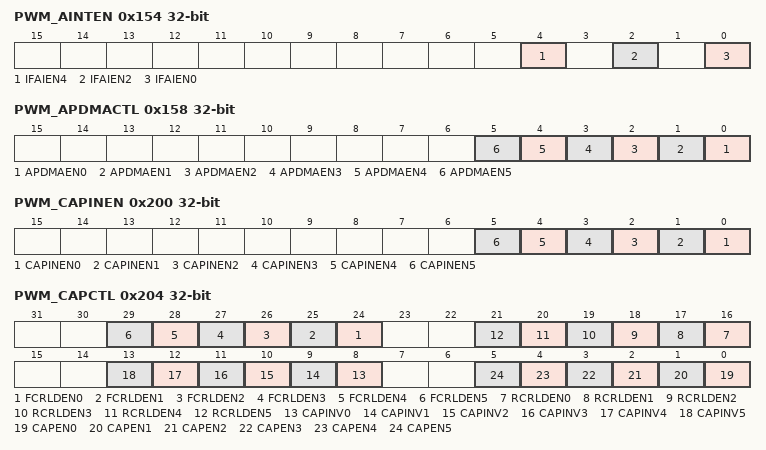
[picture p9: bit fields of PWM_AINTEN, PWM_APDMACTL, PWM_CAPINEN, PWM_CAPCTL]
0x154 PWM_AINTEN — PWM Accumulator Interrupt Enable Register
  [all] fields
    0=Interrupt Flag accumulator interrupt Disabled; 1=Interrupt Flag accumulator interrupt Enabled
  [4] IFAIEN4 — PWM_CH4 Interrupt Flag Accumulator Interrupt Enable Bits
  [2] IFAIEN2 — PWM_CH2 Interrupt Flag Accumulator Interrupt Enable Bits
  [0] IFAIEN0 — PWM_CH0 Interrupt Flag Accumulator Interrupt Enable Bits
0x158 PWM_APDMACTL — PWM Accumulator PDMA Control Register
  [all] fields
    0=Channel n PDMA function Disabled; 1=Channel n PDMA function Enabled for the channel n to trigger PDMA to transfer memory data to register
  [n] APDMAEN{n} (n=0..5) — Channel n Accumulator PDMA Enable Bits
0x200 PWM_CAPINEN — PWM Capture Input Enable Register
  [all] fields
    0=PWM Channel capture input path Disabled. The input of PWM channel capture function is always regarded as 0; 1=PWM Channel capture input path Enabled. The input of PWM channel capture function comes from correlative multifunction pin
  [n] CAPINEN{n} (n=0..5) — Capture Input Enable Bits
0x204 PWM_CAPCTL — PWM Capture Control Register
  [n+24] FCRLDEN{n} (n=0..5) — Falling Capture Reload Enable Bits
    0=Falling capture reload counter Disabled; 1=Falling capture reload counter Enabled
  [n+16] RCRLDEN{n} (n=0..5) — Rising Capture Reload Enable Bits
    0=Rising capture reload counter Disabled; 1=Rising capture reload counter Enabled
  [n+8] CAPINV{n} (n=0..5) — Capture Inverter Enable Bits
    0=Capture source inverter Disabled; 1=Capture source inverter Enabled. Reverse the input signal from GPIO
  [n] CAPEN{n} (n=0..5) — Capture Function Enable Bits
    0=Capture function Disabled. RCAPDAT/FCAPDAT register will not be updated; 1=Capture function Enabled. Capture latched the PWM counter value when detected rising or falling edge of input signal and saved to RCAPDAT (Rising latch) and FCAPDAT (Falling latch)
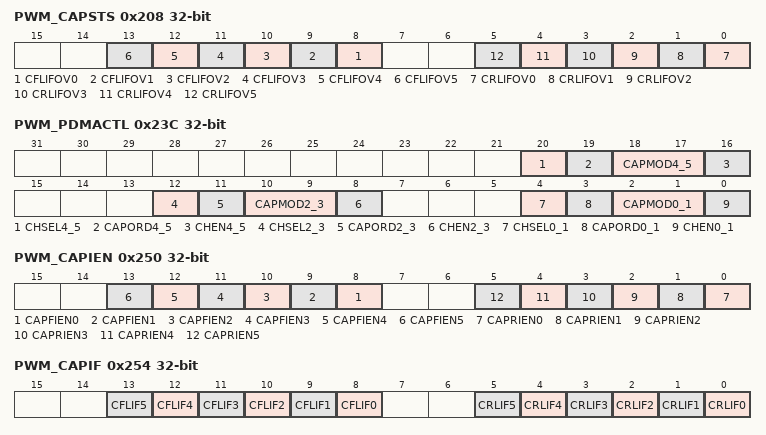
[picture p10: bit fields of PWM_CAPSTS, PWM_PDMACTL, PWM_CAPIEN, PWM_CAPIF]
0x208 PWM_CAPSTS ro — PWM Capture Status Register
  [n+8] CFLIFOV{n} (n=0..5) — Capture Falling Latch Interrupt Flag Overrun Status (Read Only). This flag indicates if falling latch happened when the corresponding CFLIF is 1. Note: This bit will be cleared automatically when user clear corresponding CFLIF.
  [n] CRLIFOV{n} (n=0..5) — Capture Rising Latch Interrupt Flag Overrun Status (Read Only). This flag indicates if rising latch happened when the corresponding CRLIF is 1. Note: This bit will be cleared automatically when user clear corresponding CRLIF.
{0x20C+8i} PWM_RCAPDAT{i} ro (i=0..5) — PWM Rising Capture Data Register {i}
  [15:0] RCAPDAT — PWM Rising Capture Data Register (Read Only). When rising capture condition happened, the PWM counter value will be saved in this register.
{0x210+8i} PWM_FCAPDAT{i} ro (i=0..5) — PWM Falling Capture Data Register {i}
  [15:0] FCAPDAT — PWM Falling Capture Data Register (Read Only). When falling capture condition happened, the PWM counter value will be saved in this register.
0x23C PWM_PDMACTL — PWM PDMA Control Register
  [20] CHSEL4_5 — Select Channel 4/5 to Do PDMA Transfer. Note: If the PDMA function is not supported, this bit field will become invalid.
    0=Channel4; 1=Channel5
  [19] CAPORD4_5 — Capture Channel 4/5 Rising/Falling Order. Note: If the PDMA function is not supported, this bit field will become invalid.
    0=PWM_FCAPDAT4/5 is the first captured data to memory; 1=PWM_RCAPDAT4/5 is the first captured data to memory
  [18:17] CAPMOD4_5 — Select PWM_RCAPDAT4/5 or PWM_FCAPDAT4/5 to Do PDMA Transfer. Note: If the PDMA function is not supported, this bit field will become invalid.
    1=PWM_RCAPDAT4/5; 2=PWM_FCAPDAT4/5; 3=Both PWM_RCAPDAT4/5 and PWM_FCAPDAT4/5
  [16] CHEN4_5 — Channel 4/5 PDMA Enable Bit. Note: If the PDMA function is not supported, this bit field will become invalid.
    0=Channel 4/5 PDMA function Disabled; 1=Channel 4/5 PDMA function Enabled for the channel 4/5 captured data and transfer to memory
  [12] CHSEL2_3 — Select Channel 2/3 to Do PDMA Transfer. Note: If the PDMA function is not supported, this bit field will become invalid.
    0=Channel2; 1=Channel3
  [11] CAPORD2_3 — Capture Channel 2/3 Rising/Falling Order. Note: If the PDMA function is not supported, this bit field will become invalid.
    0=PWM_FCAPDAT2/3 is the first captured data to memory; 1=PWM_RCAPDAT2/3 is the first captured data to memory
  [10:9] CAPMOD2_3 — Select PWM_RCAPDAT2/3 or PWM_FCAODAT2/3 to Do PDMA Transfer. Note: If the PDMA function is not supported, this bit field will become invalid.
    1=PWM_RCAPDAT2/3; 2=PWM_FCAPDAT2/3; 3=Both PWM_RCAPDAT2/3 and PWM_FCAPDAT2/3
  [8] CHEN2_3 — Channel 2/3 PDMA Enable Bit. Note: If the PDMA function is not supported, this bit field will become invalid.
    0=Channel 2/3 PDMA function Disabled; 1=Channel 2/3 PDMA function Enabled for the channel 2/3 captured data and transfer to memory
  [4] CHSEL0_1 — Select Channel 0/1 to Do PDMA Transfer. Note: If the PDMA function is not supported, this bit field will become invalid.
    0=Channel0; 1=Channel1
  [3] CAPORD0_1 — Capture Channel 0/1 Rising/Falling Order. Note: If the PDMA function is not supported, this bit field will become invalid.
    0=PWM_FCAPDAT0/1 is the first captured data to memory; 1=PWM_RCAPDAT0/1 is the first captured data to memory
  [2:1] CAPMOD0_1 — Select PWM_RCAPDAT0/1 or PWM_FCAPDAT0/1 to Do PDMA Transfer. Note: If the PDMA function is not supported, this bit field will become invalid.
    1=PWM_RCAPDAT0/1; 2=PWM_FCAPDAT0/1; 3=Both PWM_RCAPDAT0/1 and PWM_FCAPDAT0/1
  [0] CHEN0_1 — Channel 0/1 PDMA Enable Bit. Note: If the PDMA function is not supported, this bit field will become invalid.
    0=Channel 0/1 PDMA function Disabled; 1=Channel 0/1 PDMA function Enabled for the channel 0/1 captured data and transfer to memory
0x240 PWM_PDMACAP0_1 ro — PWM Capture Channel 01 PDMA Register
  [15:0] CAPBUF — PWM Capture PDMA Register (Read Only). This register is used as a buffer to transfer PWM capture rising or falling data to memory by PDMA. Note: If the PDMA function is not supported, this bit field will become invalid.
0x244 PWM_PDMACAP2_3 ro — PWM Capture Channel 23 PDMA Register
  fields as PWM_PDMACAP0_1
0x248 PWM_PDMACAP4_5 ro — PWM Capture Channel 45 PDMA Register
  fields as PWM_PDMACAP0_1
0x250 PWM_CAPIEN — PWM Capture Interrupt Enable Register
  [n+8] CAPFIEN{n} (n=0..5) — PWM Capture Falling Latch Interrupt Enable Bits
    0=Capture falling edge latch interrupt Disabled; 1=Capture falling edge latch interrupt Enabled
  [n] CAPRIEN{n} (n=0..5) — PWM Capture Rising Latch Interrupt Enable Bits
    0=Capture rising edge latch interrupt Disabled; 1=Capture rising edge latch interrupt Enabled
0x254 PWM_CAPIF — PWM Capture Interrupt Flag Register
  [n+8] CFLIF{n} (n=0..5) — PWM Capture Falling Latch Interrupt Flag. Note 1: When Capture with PDMA operating, CAPIF corresponding channel CFLIF will be cleared by hardware after PDMA transfer data. Note 2: This bit is cleared by writing 1 to it.
    0=No capture falling latch condition happened; 1=Capture falling latch condition happened, this flag will be set to high
  [n] CRLIF{n} (n=0..5) — PWM Capture Rising Latch Interrupt Flag. Note 1: When Capture with PDMA operating, CAPIF corresponding channel CRLIF will be cleared by hardware after PDMA transfer data. Note 2: This bit is cleared by writing 1 to it.
    0=No capture rising latch condition happened; 1=Capture rising latch condition happened, this flag will be set to high
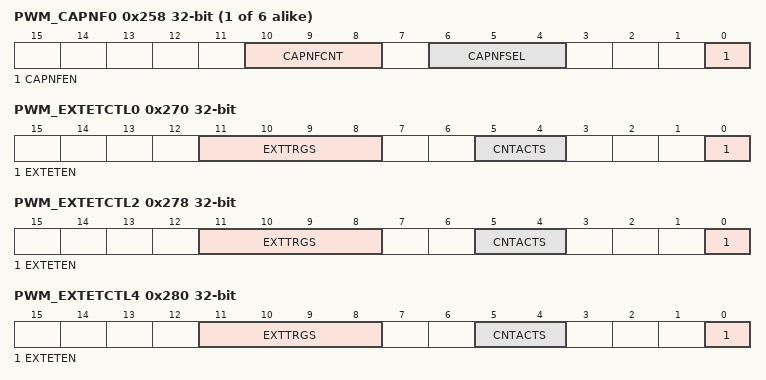
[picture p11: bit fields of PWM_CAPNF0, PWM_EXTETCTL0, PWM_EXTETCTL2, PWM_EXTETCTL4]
{0x258+4i} PWM_CAPNF{i} (i=0..5) — PWM Capture Input Noise Filter Register {i}
  [10:8] CAPNFCNT — Capture Edge Detector Noise Filter Count. The register bits control the capture filter counter to count from 0 to CAPNFCNT.
  [6:4] CAPNFSEL — Capture Edge Detector Noise Filter Clock Selection
    0=Filter clock = PCLK; 1=Filter clock = PCLK/2; 2=Filter clock = PCLK/4; 3=Filter clock = PCLK/8; 4=Filter clock = PCLK/16; 5=Filter clock = PCLK/32; 6=Filter clock = PCLK/64; 7=Filter clock = PCLK/128
  [0] CAPNFEN — Capture Noise Filter Enable Bit
    0=Capture Noise Filter function Disabled; 1=Capture Noise Filter function Enabled
0x270 PWM_EXTETCTL0 — PWM External Event Trigger Control Register 0
  [11:8] EXTTRGS — External Trigger Selection
    {v}=INT{v} (v=0..7)
  [5:4] CNTACTS — Counter Action Selection
    0=Counter reset; 1=Counter start; 2=Counter reset and start; 3=Reseved
  [0] EXTETEN — External Event Trigger Enable Bit
    0=External Event Trigger function Disabled; 1=External Event Trigger function Enabled
0x278 PWM_EXTETCTL2 — PWM External Event Trigger Control Register 2
  fields as PWM_EXTETCTL0
0x280 PWM_EXTETCTL4 — PWM External Event Trigger Control Register 4
  fields as PWM_EXTETCTL0
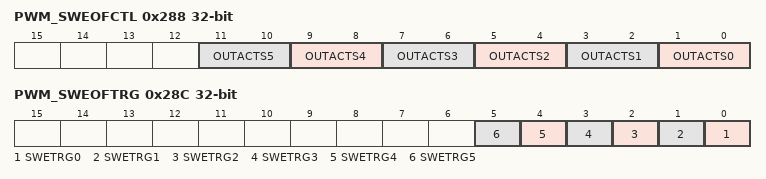
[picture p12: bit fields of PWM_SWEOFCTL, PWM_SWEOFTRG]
0x288 PWM_SWEOFCTL — PWM Software Event Output Force Control Register
  [all] fields
    0=Do nothing; 1=PWM output Low; 2=PWM output High; 3=PWM output Toggle
  [2n+1:2n] OUTACTS{n} (n=0..5) — Output Action Selection
0x28C PWM_SWEOFTRG — PWM Software Event Output Force Trigger Register
  [n] SWETRG{n} (n=0..5) — Software Event Trigger. Write 1 to this bit will change PWM output status according to OUTACTSn in PWMx_SWEOFCTL setting. Note: This bit will auto cleared by hardware.
0x304 PWM_PBUF0 ro — PWM PERIOD0 Buffer
  [15:0] PBUF — PWM Period Register Buffer (Read Only). Used as PERIOD active register.
0x30C PWM_PBUF2 ro — PWM PERIOD2 Buffer
  fields as PWM_PBUF0
0x314 PWM_PBUF4 ro — PWM PERIOD4 Buffer
  fields as PWM_PBUF0
{0x31C+4i} PWM_CMPBUF{i} ro (i=0..5) — PWM CMPDAT{i} Buffer
  [15:0] CMPBUF — PWM Comparator Register Buffer (Read Only). Used as CMP active register.

## PWM1 — PWM Register Map
Base 0x4005D000
Registers as PWM0; these are added or differ:
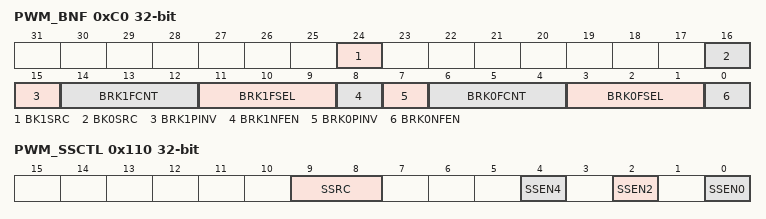
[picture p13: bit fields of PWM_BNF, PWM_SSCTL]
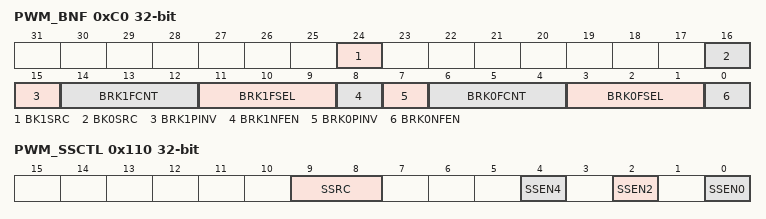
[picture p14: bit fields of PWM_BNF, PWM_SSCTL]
0xC0 PWM_BNF — PWM Brake Noise Filter Register
  fields as PWM0.PWM_BNF
0x110 PWM_SSCTL — PWM Synchronous Start Control Register
  fields as PWM0.PWM_SSCTL
0x114 PWM_SSTRG wo — PWM Synchronous Start Trigger Register
  fields as PWM0.PWM_SSTRG

## PWM0_NS — PWMNS Register Map
Base 0x5005C000
Same registers: PWM1_NS 0x5005D000
Registers as PWM0; these are added or differ:
0xC0 PWM_BNF — PWM Brake Noise Filter Register
  fields as PWM0.PWM_BNF
0x110 PWM_SSCTL — PWM Synchronous Start Control Register
  fields as PWM0.PWM_SSCTL
0x114 PWM_SSTRG wo — PWM Synchronous Start Trigger Register
  fields as PWM0.PWM_SSTRG
